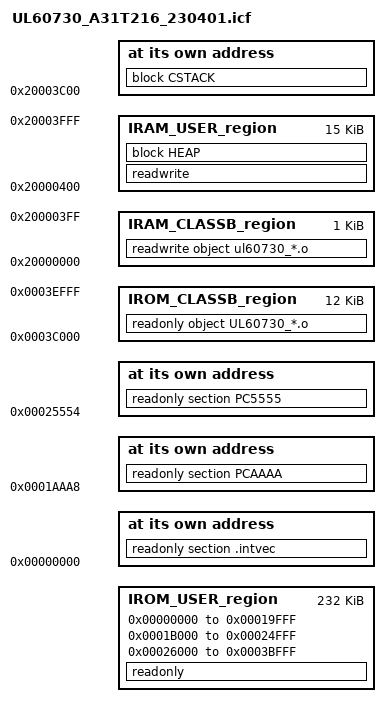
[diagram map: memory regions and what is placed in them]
/**
*******************************************************************************
* @file         UL60730_A31T216_*.icf
* @author       ABOV R&D Division
* @brief        Memory Section Handling
*
* Copyright 2023 ABOV Semiconductor Co.,Ltd. All rights reserved.
*
* This file is licensed under terms that are found in the LICENSE file
* located at Document directory.
* If this file is delivered or shared without applicable license terms,
* the terms of the BSD-3-Clause license shall be applied.
* Reference: https://opensource.org/licenses/BSD-3-Clause
******************************************************************************/


/*###ICF### Section handled by ICF editor, don't touch! ****/
/*-Editor annotation file-*/
/* IcfEditorFile="$TOOLKIT_DIR$\config\ide\IcfEditor\cortex_v1_1.xml" */


//************************************************************************************/
//********************************   A31T216   ***************************************/
//************************************************************************************/

//_____________________________ Regions - Specials ___________________________________

define memory mem with size = 4G;

define symbol __ICFEDIT_intvec_start__ = 0x00000000;

//_____________________________ Regions - IROM USER __________________________________

define symbol __ICFEDIT_region_IROM_USER1_start__ = 0x00000000;         // User1
define symbol __ICFEDIT_region_IROM_USER1_end__   = 0x00019FFF;
define symbol __ICFEDIT_region_IROM_USER2_start__ = 0x0001B000;         // User2
define symbol __ICFEDIT_region_IROM_USER2_end__   = 0x00024FFF;
define symbol __ICFEDIT_region_IROM_USER3_start__ = 0x00026000;         // User3
define symbol __ICFEDIT_region_IROM_USER3_end__   = 0x0003BFFF;

define region IROM_USER_region = mem:[from __ICFEDIT_region_IROM_USER1_start__ to __ICFEDIT_region_IROM_USER1_end__]
                               | mem:[from __ICFEDIT_region_IROM_USER2_start__ to __ICFEDIT_region_IROM_USER2_end__]
                               | mem:[from __ICFEDIT_region_IROM_USER3_start__ to __ICFEDIT_region_IROM_USER3_end__];

//_____________________________ Regions - IROM UL60730  _______________________________

define symbol __ICFEDIT_region_IROM_CLASSB_start__ = 0x0003C000;        // UL60730 CLASS B
define symbol __ICFEDIT_region_IROM_CLASSB_end__   = 0x0003EFFF;

define region IROM_CLASSB_region = mem:[from __ICFEDIT_region_IROM_CLASSB_start__ to __ICFEDIT_region_IROM_CLASSB_end__];							  

//_____________________________ Regions - EROM _______________________________________

define symbol __ICFEDIT_region_EROM1_start__ = 0x0;
define symbol __ICFEDIT_region_EROM1_end__   = 0x0;

define region EROM_region = mem:[from __ICFEDIT_region_EROM1_start__ to __ICFEDIT_region_EROM1_end__];

//_____________________________ Regions - IRAM USER __________________________________

define symbol __ICFEDIT_region_IRAM_USER1_start__  = 0x20000400;        // User1
define symbol __ICFEDIT_region_IRAM_USER1_end__    = 0x20003FFF;    

define region IRAM_USER_region = mem:[from __ICFEDIT_region_IRAM_USER1_start__ to __ICFEDIT_region_IRAM_USER1_end__];							  

//_____________________________ Regions - IRAM UL60730 _______________________________

define symbol __ICFEDIT_region_IRAM_CLASSB_start__ = 0x20000000;        // UL60730 CLASS B
define symbol __ICFEDIT_region_IRAM_CLASSB_end__   = 0x200003FF;

define region IRAM_CLASSB_region = mem:[from __ICFEDIT_region_IRAM_CLASSB_start__ to __ICFEDIT_region_IRAM_CLASSB_end__];							  

//_____________________________ Regions - ERAM _______________________________________

define symbol __ICFEDIT_region_ERAM1_start__ = 0x0;
define symbol __ICFEDIT_region_ERAM1_end__   = 0x0;

define region ERAM_region = mem:[from __ICFEDIT_region_ERAM1_start__ to __ICFEDIT_region_ERAM1_end__];

//_____________________________ Regions - STACK & ETC ________________________________

define symbol __ICFEDIT_size_cstack__ = 0x400;      // Stack Sizes 
define symbol __ICFEDIT_size_heap__   = 0x000;

define block CSTACK    with alignment = 8, size = __ICFEDIT_size_cstack__   { };
define block HEAP      with alignment = 8, size = __ICFEDIT_size_heap__     { };

//_____________________________ Place - Specials _____________________________________

place at address mem:__ICFEDIT_intvec_start__ { readonly section .intvec };

//_____________________________ Place - IROM USER ____________________________________

place in IROM_USER_region  { readonly };

//_____________________________ Place - IROM UL60730 _________________________________

place in IROM_CLASSB_region { readonly object UL60730_*.o };

place at address mem: 0x0001AAA8 { readonly section PCAAAA };
place at address mem: 0x00025554 { readonly section PC5555 };

//_____________________________ Place - EROM _________________________________________

place in EROM_region        { readonly section application_specific_ro };

//_____________________________ Place - IRAM USER ____________________________________

place in IRAM_USER_region   { readwrite, block HEAP };

//_____________________________ Place - IRAM UL60730 _________________________________

place in IRAM_CLASSB_region  { readwrite object ul60730_*.o };

//_____________________________ Place - ERAM _________________________________________

place in ERAM_region        { readwrite section application_specific_rw };

//_____________________________ Place - STACK & ETC___________________________________

place at address mem:(__ICFEDIT_region_IRAM_USER1_end__-(__ICFEDIT_size_cstack__ - 0x1)) { block CSTACK }; 

//_____________________________ Initialize ___________________________________________

do not initialize  { section .noinit };

initialize by copy { readwrite };
if (isdefinedsymbol(__USE_DLIB_PERTHREAD))
{
  // Required in a multi-threaded application
  initialize by copy with packing = none { section __DLIB_PERTHREAD };
}

initialize by copy {rw, ro code object a31t21x_fmc.o};  // Code Flash Memory Driver is placed at sram


